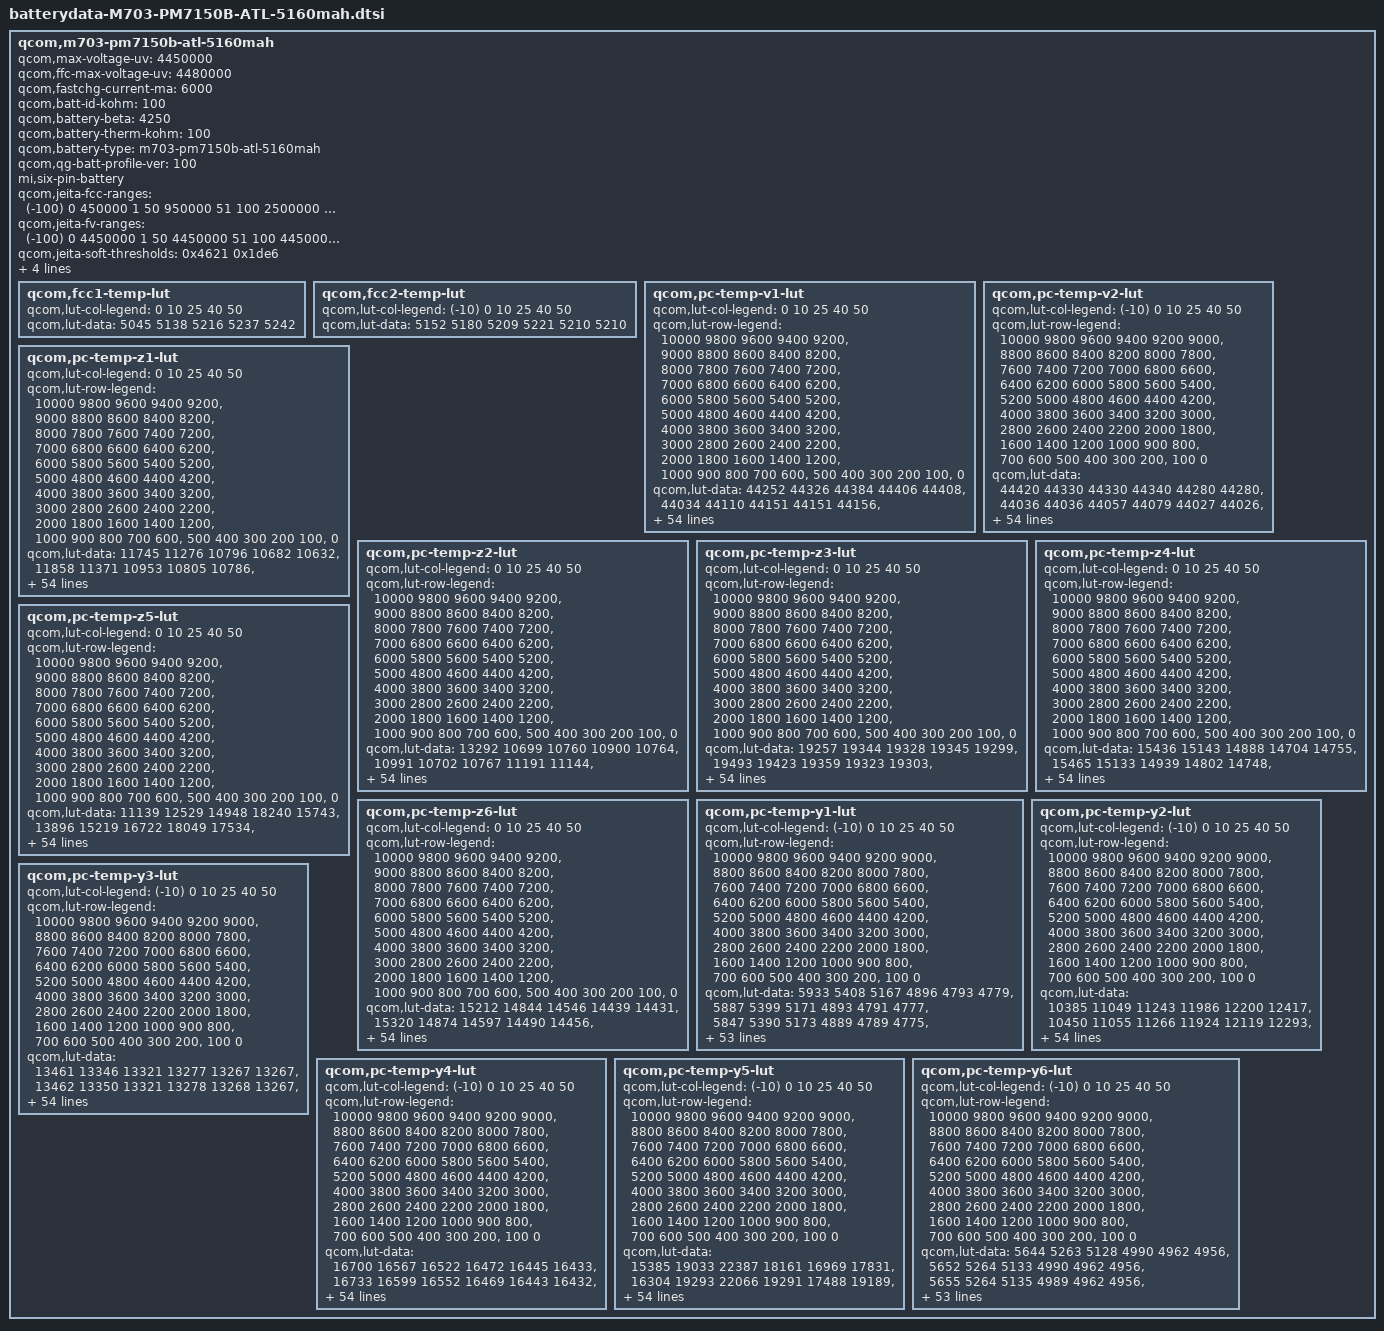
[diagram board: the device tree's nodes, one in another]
/*
 * Copyright (c) 2019, The Linux Foundation. All rights reserved.
 * Copyright (C) 2021 XiaoMi, Inc.
 *
 * This program is free software; you can redistribute it and/or modify
 * it under the terms of the GNU General Public License version 2 and
 * only version 2 as published by the Free Software Foundation.
 *
 * This program is distributed in the hope that it will be useful,
 * but WITHOUT ANY WARRANTY; without even the implied warranty of
 * MERCHANTABILITY or FITNESS FOR A PARTICULAR PURPOSE.  See the
 * GNU General Public License for more details.
 */
/* 4622819_LC_M700_ATL_5160mAH_PM7150B_averaged_Master_May26th2020 */

 qcom,m703-pm7150b-atl-5160mah {
	qcom,max-voltage-uv = <4450000>;
	qcom,ffc-max-voltage-uv = <4480000>;
	//qcom,fg-cc-cv-threshold-uv = <4440000>;
	qcom,fastchg-current-ma = <6000>;
	qcom,batt-id-kohm = <100>;
	qcom,battery-beta = <4250>;
	qcom,battery-therm-kohm = <100>;
	qcom,battery-type = "m703-pm7150b-atl-5160mah";
	qcom,qg-batt-profile-ver = <100>;
	mi,six-pin-battery;

	qcom,jeita-fcc-ranges = <(-100)  0   450000
                                1  50   950000
				51  100  2500000
				101 150  4000000
				151 480  6000000
				481 580  2500000>;

	qcom,jeita-fv-ranges = <(-100)   0   4450000
                                1   50   4450000
				51  100  4450000
				101 150  4450000
				151 480  4480000
				481 580  4100000>;

	/* COOL = 15 degc, WARM = 48 degC */
	qcom,jeita-soft-thresholds = <0x4621 0x1de6>;
	/* COLD = -10 degC, HOT = 58 degC*/
	qcom,jeita-hard-thresholds = <0x6226 0x15f7>;
	/* COOL hys = 18 degC, WARM hys = 45 degC */
	qcom,jeita-soft-hys-thresholds = <0x4206 0x20b8>;
	qcom,jeita-soft-fcc-ua = <4100000 2500000>;
	qcom,jeita-soft-fv-uv = <4450000 4100000>;

	qcom,fcc1-temp-lut {
		qcom,lut-col-legend = <0 10 25 40 50>;
		qcom,lut-data = <5045 5138 5216 5237 5242>;
	};

	qcom,fcc2-temp-lut {
		qcom,lut-col-legend = <(-10) 0 10 25 40 50>;
		qcom,lut-data = <5152 5180 5209 5221 5210 5210>;
	};

	qcom,pc-temp-v1-lut {
		qcom,lut-col-legend = <0 10 25 40 50>;
		qcom,lut-row-legend = <10000 9800 9600 9400 9200>,
			<9000 8800 8600 8400 8200>,
			<8000 7800 7600 7400 7200>,
			<7000 6800 6600 6400 6200>,
			<6000 5800 5600 5400 5200>,
			<5000 4800 4600 4400 4200>,
			<4000 3800 3600 3400 3200>,
			<3000 2800 2600 2400 2200>,
			<2000 1800 1600 1400 1200>,
			<1000 900 800 700 600>,
			<500 400 300 200 100>,
			<0>;
		qcom,lut-data = <44252 44326 44384 44406 44408>,
			<44034 44110 44151 44151 44156>,
			<43814 43893 43932 43929 43933>,
			<43596 43678 43715 43713 43716>,
			<43372 43463 43496 43496 43499>,
			<43136 43239 43276 43280 43282>,
			<42894 43001 43044 43054 43058>,
			<42654 42757 42801 42816 42824>,
			<42412 42515 42556 42574 42586>,
			<42174 42272 42311 42332 42346>,
			<41943 42033 42067 42089 42104>,
			<41717 41796 41827 41849 41865>,
			<41494 41564 41590 41611 41628>,
			<41274 41340 41357 41377 41395>,
			<41060 41124 41132 41150 41170>,
			<40858 40913 40914 40930 40950>,
			<40663 40705 40705 40719 40739>,
			<40470 40503 40503 40516 40533>,
			<40278 40320 40312 40323 40336>,
			<40090 40153 40138 40144 40153>,
			<39912 39968 39964 39969 39976>,
			<39745 39732 39752 39765 39775>,
			<39557 39486 39506 39530 39549>,
			<39288 39282 39290 39311 39335>,
			<39026 39101 39109 39118 39140>,
			<38894 38951 38952 38947 38963>,
			<38820 38835 38821 38810 38821>,
			<38753 38735 38710 38696 38703>,
			<38676 38637 38608 38592 38595>,
			<38599 38542 38510 38493 38492>,
			<38530 38460 38422 38402 38399>,
			<38464 38389 38345 38321 38312>,
			<38404 38328 38276 38247 38232>,
			<38346 38271 38215 38179 38160>,
			<38292 38221 38163 38120 38096>,
			<38250 38175 38115 38063 38034>,
			<38220 38137 38067 38004 37962>,
			<38186 38099 38020 37944 37883>,
			<38126 38040 37957 37872 37799>,
			<38033 37952 37873 37785 37715>,
			<37926 37847 37772 37684 37619>,
			<37801 37726 37655 37565 37500>,
			<37656 37583 37517 37427 37359>,
			<37478 37407 37350 37266 37195>,
			<37329 37241 37191 37121 37051>,
			<37214 37130 37087 37027 36962>,
			<37167 37101 37060 37004 36939>,
			<37136 37082 37044 36987 36923>,
			<37110 37052 37024 36970 36911>,
			<37073 37023 36985 36925 36866>,
			<36921 36817 36749 36653 36609>,
			<36484 36368 36304 36203 36178>,
			<35894 35765 35710 35614 35605>,
			<35074 34925 34895 34801 34835>,
			<33639 33502 33608 33529 33659>,
			<30000 30000 30000 30000 30000>;
	};

	qcom,pc-temp-v2-lut {
		qcom,lut-col-legend = <(-10) 0 10 25 40 50>;
		qcom,lut-row-legend = <10000 9800 9600 9400 9200 9000>,
			<8800 8600 8400 8200 8000 7800>,
			<7600 7400 7200 7000 6800 6600>,
			<6400 6200 6000 5800 5600 5400>,
			<5200 5000 4800 4600 4400 4200>,
			<4000 3800 3600 3400 3200 3000>,
			<2800 2600 2400 2200 2000 1800>,
			<1600 1400 1200 1000 900 800>,
			<700 600 500 400 300 200>,
			<100 0>;
		qcom,lut-data = <44420 44330 44330 44340 44280 44280>,
			<44036 44036 44057 44079 44027 44026>,
			<43696 43766 43800 43832 43785 43784>,
			<43412 43523 43565 43602 43557 43556>,
			<43174 43307 43351 43388 43344 43344>,
			<42943 43090 43132 43169 43126 43127>,
			<42699 42858 42897 42934 42893 42896>,
			<42456 42621 42656 42692 42654 42658>,
			<42218 42383 42416 42449 42414 42419>,
			<41985 42139 42173 42205 42170 42176>,
			<41753 41898 41933 41962 41930 41936>,
			<41509 41658 41696 41722 41692 41698>,
			<41271 41422 41463 41484 41458 41464>,
			<41079 41199 41233 41252 41229 41234>,
			<40934 40986 41006 41026 41006 41010>,
			<40759 40781 40787 40807 40790 40793>,
			<40461 40590 40577 40595 40580 40584>,
			<40099 40398 40374 40391 40377 40382>,
			<39823 40171 40182 40200 40186 40191>,
			<39604 39906 39999 40017 40005 40008>,
			<39397 39647 39791 39817 39809 39812>,
			<39183 39400 39523 39586 39582 39589>,
			<38975 39168 39253 39353 39351 39362>,
			<38778 38970 39040 39134 39139 39152>,
			<38582 38794 38856 38924 38937 38950>,
			<38425 38638 38698 38756 38772 38786>,
			<38321 38496 38561 38625 38644 38659>,
			<38238 38368 38441 38512 38533 38548>,
			<38165 38248 38331 38405 38430 38441>,
			<38100 38134 38231 38307 38334 38341>,
			<38040 38048 38138 38217 38246 38250>,
			<37983 37986 38048 38136 38164 38167>,
			<37928 37936 37968 38060 38088 38089>,
			<37871 37891 37903 37991 38019 38016>,
			<37815 37851 37847 37925 37954 37945>,
			<37755 37811 37796 37854 37872 37854>,
			<37689 37776 37756 37779 37763 37726>,
			<37619 37736 37711 37699 37650 37596>,
			<37543 37680 37645 37614 37553 37494>,
			<37461 37603 37560 37523 37462 37400>,
			<37369 37503 37457 37429 37364 37302>,
			<37260 37351 37325 37330 37261 37200>,
			<37139 37182 37182 37213 37141 37080>,
			<37006 37013 37028 37074 37001 36941>,
			<36880 36859 36884 36924 36876 36816>,
			<36767 36774 36814 36886 36849 36791>,
			<36719 36742 36769 36868 36835 36779>,
			<36663 36709 36731 36847 36820 36762>,
			<36612 36661 36673 36819 36793 36726>,
			<36550 36578 36535 36741 36679 36571>,
			<36438 36362 36169 36437 36298 36175>,
			<36180 35898 35592 35918 35774 35633>,
			<35673 35197 34836 35248 35070 34918>,
			<34885 34243 33745 34328 34082 33902>,
			<33994 32837 32031 32879 32605 32572>,
			<32884 29022 27352 27492 28129 28778>;
	};

	qcom,pc-temp-z1-lut {
		qcom,lut-col-legend = <0 10 25 40 50>;
		qcom,lut-row-legend = <10000 9800 9600 9400 9200>,
			<9000 8800 8600 8400 8200>,
			<8000 7800 7600 7400 7200>,
			<7000 6800 6600 6400 6200>,
			<6000 5800 5600 5400 5200>,
			<5000 4800 4600 4400 4200>,
			<4000 3800 3600 3400 3200>,
			<3000 2800 2600 2400 2200>,
			<2000 1800 1600 1400 1200>,
			<1000 900 800 700 600>,
			<500 400 300 200 100>,
			<0>;
		qcom,lut-data = <11745 11276 10796 10682 10632>,
			<11858 11371 10953 10805 10786>,
			<11881 11429 10981 10823 10802>,
			<11884 11433 10990 10831 10810>,
			<11885 11429 10986 10833 10812>,
			<11871 11424 10979 10834 10813>,
			<11847 11416 10975 10835 10814>,
			<11841 11404 10972 10834 10816>,
			<11840 11391 10970 10834 10818>,
			<11839 11374 10967 10834 10820>,
			<11830 11364 10964 10833 10821>,
			<11810 11362 10962 10832 10821>,
			<11799 11360 10961 10830 10820>,
			<11794 11354 10960 10829 10820>,
			<11790 11343 10960 10829 10821>,
			<11784 11337 10959 10831 10822>,
			<11778 11338 10959 10831 10823>,
			<11776 11340 10960 10832 10824>,
			<11776 11341 10961 10832 10825>,
			<11778 11344 10962 10833 10826>,
			<11783 11346 10963 10834 10826>,
			<11792 11348 10965 10835 10828>,
			<11796 11350 10967 10837 10829>,
			<11784 11353 10969 10839 10832>,
			<11768 11357 10972 10841 10834>,
			<11771 11361 10976 10844 10837>,
			<11795 11369 10980 10847 10838>,
			<11810 11377 10984 10850 10839>,
			<11809 11377 10988 10852 10840>,
			<11806 11369 10991 10853 10843>,
			<11807 11364 10995 10854 10847>,
			<11813 11369 10998 10856 10848>,
			<11820 11378 11002 10858 10849>,
			<11824 11384 11006 10861 10849>,
			<11828 11390 11008 10863 10851>,
			<11831 11395 11011 10865 10853>,
			<11834 11400 11015 10867 10855>,
			<11836 11403 11018 10870 10858>,
			<11841 11406 11022 10872 10860>,
			<11847 11407 11027 10874 10862>,
			<11850 11410 11031 10875 10863>,
			<11851 11423 11034 10877 10864>,
			<11855 11440 11036 10880 10865>,
			<11906 11452 11043 10884 10866>,
			<11889 11453 11048 10884 10867>,
			<11905 11451 11049 10883 10870>,
			<11903 11436 11051 10885 10869>,
			<11903 11435 11055 10886 10871>,
			<11914 11455 11056 10888 10870>,
			<11909 11443 11060 10890 10873>,
			<11935 11472 11069 10892 10875>,
			<11934 11480 11066 10897 10879>,
			<11959 11494 11079 10902 10884>,
			<11967 11497 11092 10910 10890>,
			<11967 11497 11092 10910 10890>,
			<11967 11497 11092 10910 10890>;
	};

	qcom,pc-temp-z2-lut {
		qcom,lut-col-legend = <0 10 25 40 50>;
		qcom,lut-row-legend = <10000 9800 9600 9400 9200>,
			<9000 8800 8600 8400 8200>,
			<8000 7800 7600 7400 7200>,
			<7000 6800 6600 6400 6200>,
			<6000 5800 5600 5400 5200>,
			<5000 4800 4600 4400 4200>,
			<4000 3800 3600 3400 3200>,
			<3000 2800 2600 2400 2200>,
			<2000 1800 1600 1400 1200>,
			<1000 900 800 700 600>,
			<500 400 300 200 100>,
			<0>;
		qcom,lut-data = <13292 10699 10760 10900 10764>,
			<10991 10702 10767 11191 11144>,
			<10544 10702 10937 11236 11171>,
			<10508 10698 11060 11252 11216>,
			<10480 10680 11030 11244 11268>,
			<10441 10658 10969 11219 11330>,
			<10406 10623 10931 11203 11344>,
			<10387 10588 10903 11197 11239>,
			<10374 10573 10891 11189 11139>,
			<10368 10563 10910 11151 11136>,
			<10369 10561 10945 11090 11143>,
			<10374 10583 10974 11077 11157>,
			<10381 10617 11001 11107 11211>,
			<10399 10639 11018 11131 11253>,
			<10424 10655 11025 11116 11246>,
			<10455 10672 11030 11089 11229>,
			<10492 10691 11043 11086 11234>,
			<10520 10708 11068 11109 11294>,
			<10540 10717 11079 11143 11349>,
			<10555 10722 11076 11193 11365>,
			<10564 10729 11071 11255 11377>,
			<10571 10743 11080 11302 11391>,
			<10575 10755 11114 11344 11408>,
			<10576 10751 11140 11362 11416>,
			<10577 10726 11156 11346 11323>,
			<10578 10712 11166 11309 11173>,
			<10581 10719 11125 11241 11100>,
			<10584 10727 11007 11112 11051>,
			<10590 10724 10960 11042 11034>,
			<10596 10708 10967 11028 11035>,
			<10600 10699 10980 11020 11039>,
			<10601 10707 11002 11033 11062>,
			<10604 10724 11038 11083 11134>,
			<10613 10742 11075 11138 11209>,
			<10629 10767 11114 11195 11284>,
			<10635 10785 11153 11258 11355>,
			<10637 10790 11188 11325 11408>,
			<10638 10795 11220 11396 11452>,
			<10647 10801 11250 11460 11480>,
			<10664 10811 11282 11529 11493>,
			<10670 10816 11300 11570 11508>,
			<10652 10810 11298 11555 11552>,
			<10643 10805 11291 11519 11600>,
			<10679 10810 11269 11481 11544>,
			<10443 10917 11265 11450 11442>,
			<10460 11033 11302 11490 11547>,
			<11036 11017 11273 11473 11515>,
			<10801 11223 11222 11408 11499>,
			<10323 11051 11280 11451 11673>,
			<10381 11775 11254 11653 11690>,
			<10512 11294 11307 11221 11264>,
			<10271 11384 11208 11152 11183>,
			<9929 11200 11173 11105 11185>,
			<9838 10959 11119 11027 11037>,
			<9838 10959 11119 11027 11037>,
			<9838 10959 11119 11027 11037>;
	};

	qcom,pc-temp-z3-lut {
		qcom,lut-col-legend = <0 10 25 40 50>;
		qcom,lut-row-legend = <10000 9800 9600 9400 9200>,
			<9000 8800 8600 8400 8200>,
			<8000 7800 7600 7400 7200>,
			<7000 6800 6600 6400 6200>,
			<6000 5800 5600 5400 5200>,
			<5000 4800 4600 4400 4200>,
			<4000 3800 3600 3400 3200>,
			<3000 2800 2600 2400 2200>,
			<2000 1800 1600 1400 1200>,
			<1000 900 800 700 600>,
			<500 400 300 200 100>,
			<0>;
		qcom,lut-data = <19257 19344 19328 19345 19299>,
			<19493 19423 19359 19323 19303>,
			<19581 19476 19376 19336 19310>,
			<19620 19494 19386 19345 19318>,
			<19641 19503 19391 19348 19325>,
			<19657 19508 19394 19349 19332>,
			<19667 19513 19396 19349 19334>,
			<19669 19515 19397 19347 19331>,
			<19668 19515 19398 19345 19327>,
			<19665 19510 19391 19340 19324>,
			<19660 19505 19380 19333 19321>,
			<19652 19500 19377 19330 19320>,
			<19645 19495 19376 19329 19319>,
			<19641 19488 19376 19329 19318>,
			<19637 19480 19374 19328 19316>,
			<19630 19476 19372 19326 19311>,
			<19622 19477 19370 19324 19308>,
			<19614 19479 19367 19320 19306>,
			<19604 19477 19364 19317 19304>,
			<19597 19469 19362 19315 19303>,
			<19598 19465 19360 19313 19303>,
			<19604 19474 19361 19314 19304>,
			<19609 19486 19368 19319 19310>,
			<19613 19485 19371 19326 19318>,
			<19615 19471 19372 19340 19326>,
			<19613 19464 19373 19354 19332>,
			<19602 19474 19378 19355 19333>,
			<19594 19489 19388 19352 19331>,
			<19597 19493 19392 19348 19329>,
			<19601 19494 19391 19344 19326>,
			<19602 19495 19390 19340 19323>,
			<19602 19491 19386 19336 19320>,
			<19601 19484 19381 19330 19316>,
			<19600 19479 19376 19326 19313>,
			<19599 19475 19372 19324 19308>,
			<19597 19473 19369 19322 19305>,
			<19592 19471 19367 19321 19306>,
			<19587 19470 19367 19321 19309>,
			<19583 19468 19366 19321 19310>,
			<19579 19463 19363 19322 19310>,
			<19574 19459 19361 19323 19309>,
			<19568 19454 19360 19325 19310>,
			<19559 19449 19358 19325 19313>,
			<19544 19445 19356 19324 19315>,
			<19346 19426 19350 19318 19314>,
			<19269 19408 19339 19310 19306>,
			<19315 19396 19339 19309 19303>,
			<19302 19329 19331 19308 19303>,
			<19263 19397 19333 19304 19290>,
			<19263 19293 19330 19298 19295>,
			<19262 19334 19332 19323 19310>,
			<19263 19314 19339 19321 19311>,
			<19273 19318 19339 19322 19314>,
			<19277 19335 19343 19323 19313>,
			<19277 19335 19343 19323 19313>,
			<19277 19335 19343 19323 19313>;
	};

	qcom,pc-temp-z4-lut {
		qcom,lut-col-legend = <0 10 25 40 50>;
		qcom,lut-row-legend = <10000 9800 9600 9400 9200>,
			<9000 8800 8600 8400 8200>,
			<8000 7800 7600 7400 7200>,
			<7000 6800 6600 6400 6200>,
			<6000 5800 5600 5400 5200>,
			<5000 4800 4600 4400 4200>,
			<4000 3800 3600 3400 3200>,
			<3000 2800 2600 2400 2200>,
			<2000 1800 1600 1400 1200>,
			<1000 900 800 700 600>,
			<500 400 300 200 100>,
			<0>;
		qcom,lut-data = <15436 15143 14888 14704 14755>,
			<15465 15133 14939 14802 14748>,
			<15443 15108 14898 14783 14740>,
			<15323 15064 14852 14757 14728>,
			<15197 14983 14818 14739 14715>,
			<15110 14915 14788 14724 14699>,
			<15032 14868 14762 14709 14687>,
			<14972 14830 14738 14695 14679>,
			<14924 14801 14721 14685 14672>,
			<14884 14777 14714 14682 14668>,
			<14853 14759 14708 14680 14665>,
			<14827 14741 14701 14678 14661>,
			<14804 14728 14693 14671 14656>,
			<14782 14724 14686 14665 14651>,
			<14765 14723 14680 14659 14648>,
			<14755 14720 14675 14655 14646>,
			<14749 14717 14672 14651 14643>,
			<14747 14712 14668 14648 14640>,
			<14756 14709 14667 14646 14636>,
			<14766 14706 14666 14643 14632>,
			<14763 14705 14666 14642 14630>,
			<14750 14724 14678 14649 14634>,
			<14743 14757 14719 14683 14659>,
			<14799 14785 14744 14703 14674>,
			<14872 14815 14752 14698 14674>,
			<14882 14827 14757 14689 14674>,
			<14866 14803 14748 14682 14671>,
			<14848 14767 14720 14674 14663>,
			<14830 14752 14702 14668 14656>,
			<14812 14743 14693 14663 14651>,
			<14799 14739 14688 14659 14647>,
			<14787 14738 14686 14656 14643>,
			<14780 14737 14686 14653 14640>,
			<14778 14737 14685 14652 14639>,
			<14777 14737 14685 14652 14638>,
			<14775 14736 14685 14652 14638>,
			<14768 14735 14686 14655 14641>,
			<14760 14732 14690 14662 14651>,
			<14754 14728 14692 14664 14654>,
			<14747 14725 14692 14664 14652>,
			<14738 14719 14693 14663 14649>,
			<14723 14707 14686 14659 14644>,
			<14708 14691 14673 14653 14639>,
			<14696 14680 14666 14650 14639>,
			<14840 14664 14657 14648 14635>,
			<14893 14652 14649 14642 14628>,
			<14842 14657 14639 14634 14625>,
			<14853 14724 14636 14625 14614>,
			<14887 14644 14624 14618 14616>,
			<14884 14758 14627 14623 14609>,
			<14884 14719 14640 14614 14613>,
			<14890 14744 14633 14619 14615>,
			<14889 14746 14635 14618 14613>,
			<14902 14735 14632 14619 14615>,
			<14902 14735 14632 14619 14615>,
			<14902 14735 14632 14619 14615>;
	};

	qcom,pc-temp-z5-lut {
		qcom,lut-col-legend = <0 10 25 40 50>;
		qcom,lut-row-legend = <10000 9800 9600 9400 9200>,
			<9000 8800 8600 8400 8200>,
			<8000 7800 7600 7400 7200>,
			<7000 6800 6600 6400 6200>,
			<6000 5800 5600 5400 5200>,
			<5000 4800 4600 4400 4200>,
			<4000 3800 3600 3400 3200>,
			<3000 2800 2600 2400 2200>,
			<2000 1800 1600 1400 1200>,
			<1000 900 800 700 600>,
			<500 400 300 200 100>,
			<0>;
		qcom,lut-data = <11139 12529 14948 18240 15743>,
			<13896 15219 16722 18049 17534>,
			<15543 17240 18249 20262 18782>,
			<16587 18359 19231 21770 20753>,
			<17538 19071 19724 22064 22669>,
			<18572 19865 20080 22183 24724>,
			<19588 20945 20708 22433 25377>,
			<20613 22038 21784 23165 25351>,
			<21670 22857 22372 23729 25300>,
			<22651 23503 22118 23148 25072>,
			<23403 24362 21738 21886 24647>,
			<24082 26203 21875 21618 24646>,
			<25167 27888 22933 22393 25861>,
			<27355 27918 24068 23355 26862>,
			<29673 27350 24976 24234 26259>,
			<31394 27108 25839 25025 25069>,
			<32894 29869 26603 25104 24822>,
			<33317 33339 27293 24651 25257>,
			<31928 33247 27927 24347 25979>,
			<30379 31235 28542 24957 27952>,
			<31717 30258 29081 25896 30429>,
			<37196 37257 29496 25849 30632>,
			<41470 46330 29853 24841 29143>,
			<43714 44466 29825 24139 27340>,
			<45187 32059 25486 23959 25146>,
			<43837 25250 20679 23860 23217>,
			<36584 26555 21122 24126 23289>,
			<31892 29169 24073 25365 24776>,
			<32577 32505 27321 26780 26433>,
			<34163 37443 31129 28379 28024>,
			<35964 40786 34618 29887 29631>,
			<38384 42055 36673 30684 31076>,
			<40867 42917 38185 31183 32433>,
			<43312 43735 39388 32019 33373>,
			<45566 44543 40547 34393 34073>,
			<46026 44891 41215 36417 34482>,
			<44561 44774 41188 35796 34353>,
			<43188 44476 41012 33773 33871>,
			<43286 43655 40312 32521 33385>,
			<43730 41216 36128 31839 32815>,
			<43838 39046 32772 31488 32442>,
			<42060 37911 33231 32772 34449>,
			<39443 37040 33956 34753 37647>,
			<36594 36377 32555 32708 37527>,
			<18602 35669 30300 26975 35307>,
			<11947 32409 27698 24064 28035>,
			<12784 26266 30522 25866 27587>,
			<12423 14759 27356 29400 36957>,
			<11743 28035 32088 32863 27511>,
			<11710 12778 28779 24204 33794>,
			<11747 14926 23010 44383 43324>,
			<11714 13601 25113 35484 41387>,
			<11713 13591 24041 34798 44676>,
			<12068 14472 25077 32664 37024>,
			<12068 14472 25077 32664 37024>,
			<12068 14472 25077 32664 37024>;
	};

	qcom,pc-temp-z6-lut {
		qcom,lut-col-legend = <0 10 25 40 50>;
		qcom,lut-row-legend = <10000 9800 9600 9400 9200>,
			<9000 8800 8600 8400 8200>,
			<8000 7800 7600 7400 7200>,
			<7000 6800 6600 6400 6200>,
			<6000 5800 5600 5400 5200>,
			<5000 4800 4600 4400 4200>,
			<4000 3800 3600 3400 3200>,
			<3000 2800 2600 2400 2200>,
			<2000 1800 1600 1400 1200>,
			<1000 900 800 700 600>,
			<500 400 300 200 100>,
			<0>;
		qcom,lut-data = <15212 14844 14546 14439 14431>,
			<15320 14874 14597 14490 14456>,
			<15325 14885 14591 14489 14457>,
			<15268 14875 14582 14487 14458>,
			<15205 14834 14571 14484 14457>,
			<15156 14797 14557 14478 14454>,
			<15110 14771 14546 14471 14451>,
			<15070 14749 14536 14465 14446>,
			<15036 14729 14528 14459 14441>,
			<15005 14711 14519 14454 14438>,
			<14978 14696 14512 14451 14435>,
			<14954 14684 14506 14447 14432>,
			<14934 14673 14502 14443 14430>,
			<14917 14666 14498 14440 14427>,
			<14903 14660 14494 14437 14424>,
			<14892 14656 14491 14434 14421>,
			<14883 14654 14488 14431 14418>,
			<14878 14653 14485 14428 14415>,
			<14877 14650 14483 14425 14413>,
			<14876 14644 14481 14423 14411>,
			<14875 14642 14481 14422 14410>,
			<14874 14656 14486 14425 14412>,
			<14874 14677 14508 14442 14426>,
			<14900 14688 14522 14456 14438>,
			<14936 14696 14528 14463 14444>,
			<14939 14699 14531 14467 14448>,
			<14928 14695 14529 14466 14447>,
			<14918 14689 14524 14461 14443>,
			<14914 14686 14519 14456 14439>,
			<14910 14685 14516 14452 14436>,
			<14907 14684 14513 14448 14432>,
			<14903 14681 14510 14444 14429>,
			<14901 14678 14508 14441 14426>,
			<14902 14678 14506 14438 14423>,
			<14902 14677 14504 14437 14420>,
			<14903 14677 14503 14436 14419>,
			<14901 14677 14504 14437 14421>,
			<14899 14678 14506 14439 14427>,
			<14900 14678 14507 14441 14429>,
			<14902 14677 14507 14442 14428>,
			<14903 14676 14506 14443 14427>,
			<14901 14672 14503 14442 14426>,
			<14898 14667 14498 14439 14425>,
			<14895 14665 14496 14438 14426>,
			<14870 14655 14489 14435 14424>,
			<14858 14644 14482 14428 14417>,
			<14857 14642 14478 14424 14414>,
			<14856 14637 14473 14419 14410>,
			<14855 14639 14469 14414 14403>,
			<14857 14639 14470 14414 14403>,
			<14865 14647 14478 14424 14413>,
			<14874 14653 14480 14426 14416>,
			<14884 14663 14483 14427 14418>,
			<14904 14676 14486 14430 14419>,
			<14904 14676 14486 14430 14419>,
			<14904 14676 14486 14430 14419>;
	};

	qcom,pc-temp-y1-lut {
		qcom,lut-col-legend = <(-10) 0 10 25 40 50>;
		qcom,lut-row-legend = <10000 9800 9600 9400 9200 9000>,
			<8800 8600 8400 8200 8000 7800>,
			<7600 7400 7200 7000 6800 6600>,
			<6400 6200 6000 5800 5600 5400>,
			<5200 5000 4800 4600 4400 4200>,
			<4000 3800 3600 3400 3200 3000>,
			<2800 2600 2400 2200 2000 1800>,
			<1600 1400 1200 1000 900 800>,
			<700 600 500 400 300 200>,
			<100 0>;
		qcom,lut-data = <5933 5408 5167 4896 4793 4779>,
			<5887 5399 5171 4893 4791 4777>,
			<5847 5390 5173 4889 4789 4775>,
			<5815 5381 5173 4886 4788 4774>,
			<5794 5374 5172 4882 4786 4772>,
			<5786 5369 5169 4879 4785 4771>,
			<5796 5366 5163 4876 4784 4770>,
			<5812 5364 5154 4873 4783 4769>,
			<5811 5360 5151 4870 4781 4768>,
			<5792 5355 5149 4867 4778 4768>,
			<5779 5352 5147 4865 4777 4768>,
			<5791 5354 5143 4863 4777 4768>,
			<5810 5356 5138 4862 4777 4769>,
			<5816 5355 5134 4860 4777 4769>,
			<5818 5350 5131 4858 4777 4769>,
			<5819 5347 5130 4857 4777 4769>,
			<5820 5350 5131 4857 4777 4768>,
			<5822 5356 5133 4856 4777 4767>,
			<5825 5362 5133 4856 4777 4767>,
			<5832 5368 5130 4856 4777 4768>,
			<5837 5371 5127 4856 4777 4768>,
			<5840 5365 5122 4858 4778 4768>,
			<5842 5358 5117 4861 4779 4769>,
			<5844 5359 5118 4861 4780 4770>,
			<5846 5369 5123 4861 4780 4771>,
			<5847 5377 5129 4861 4781 4772>,
			<5840 5380 5135 4863 4781 4773>,
			<5828 5382 5138 4866 4782 4773>,
			<5827 5381 5138 4869 4783 4773>,
			<5836 5377 5136 4872 4784 4773>,
			<5842 5375 5134 4874 4785 4773>,
			<5842 5377 5132 4876 4788 4774>,
			<5842 5380 5130 4878 4791 4775>,
			<5842 5378 5136 4880 4792 4777>,
			<5842 5371 5149 4883 4792 4779>,
			<5842 5367 5153 4885 4793 4780>,
			<5839 5378 5150 4887 4794 4780>,
			<5831 5392 5146 4889 4794 4780>,
			<5821 5390 5144 4891 4796 4780>,
			<5801 5378 5143 4894 4798 4782>,
			<5789 5373 5144 4895 4798 4782>,
			<5794 5380 5156 4895 4798 4783>,
			<5804 5386 5169 4897 4798 4784>,
			<5824 5388 5178 4902 4799 4786>,
			<5831 5410 5175 4903 4801 4784>,
			<5836 5396 5187 4904 4799 4788>,
			<5866 5402 5184 4906 4803 4786>,
			<5873 5413 5185 4908 4802 4787>,
			<5884 5408 5185 4912 4804 4787>,
			<5900 5404 5188 4913 4803 4788>,
			<5944 5444 5199 4915 4805 4788>,
			<6017 5512 5192 4919 4807 4790>,
			<6152 5637 5230 4926 4810 4794>,
			<6388 5885 5359 4940 4813 4798>,
			<6388 5885 5359 4940 4813 4798>,
			<6388 5885 5359 4940 4813 4798>;
	};

	qcom,pc-temp-y2-lut {
		qcom,lut-col-legend = <(-10) 0 10 25 40 50>;
		qcom,lut-row-legend = <10000 9800 9600 9400 9200 9000>,
			<8800 8600 8400 8200 8000 7800>,
			<7600 7400 7200 7000 6800 6600>,
			<6400 6200 6000 5800 5600 5400>,
			<5200 5000 4800 4600 4400 4200>,
			<4000 3800 3600 3400 3200 3000>,
			<2800 2600 2400 2200 2000 1800>,
			<1600 1400 1200 1000 900 800>,
			<700 600 500 400 300 200>,
			<100 0>;
		qcom,lut-data = <10385 11049 11243 11986 12200 12417>,
			<10450 11055 11266 11924 12119 12293>,
			<10528 11055 11273 11807 12041 12157>,
			<10606 11050 11269 11674 11968 12027>,
			<10671 11041 11256 11567 11905 11919>,
			<10710 11029 11238 11526 11855 11849>,
			<10729 11009 11208 11531 11819 11810>,
			<10741 10988 11172 11537 11787 11783>,
			<10741 10983 11150 11528 11750 11758>,
			<10731 10982 11134 11485 11707 11736>,
			<10725 10982 11121 11463 11670 11712>,
			<10786 10986 11108 11490 11639 11669>,
			<10884 10998 11098 11522 11612 11632>,
			<10893 11021 11101 11514 11590 11634>,
			<10837 11073 11119 11473 11570 11655>,
			<10798 11126 11147 11456 11561 11665>,
			<10851 11176 11209 11474 11560 11646>,
			<10937 11217 11291 11511 11559 11625>,
			<10960 11229 11373 11586 11582 11655>,
			<10965 11234 11462 11717 11667 11768>,
			<10966 11236 11493 11786 11754 11862>,
			<10956 11231 11454 11805 11831 11911>,
			<10926 11224 11413 11819 11909 11962>,
			<10786 11228 11419 11834 11995 12068>,
			<10195 11251 11448 11848 12083 12224>,
			<9774 11272 11469 11864 12106 12304>,
			<9737 11283 11479 11884 12024 12333>,
			<9716 11295 11488 11908 11943 12348>,
			<9707 11331 11503 11946 12013 12327>,
			<9702 11406 11520 11990 12208 12274>,
			<9698 11440 11524 11996 12308 12255>,
			<9693 11392 11501 11943 12336 12260>,
			<9688 11312 11476 11901 12359 12268>,
			<9685 11252 11469 11943 12405 12297>,
			<9682 11198 11466 12025 12458 12351>,
			<9680 11142 11458 12040 12467 12379>,
			<9677 11086 11435 12005 12410 12389>,
			<9674 11025 11402 11968 12327 12399>,
			<9672 10956 11357 11952 12222 12416>,
			<9671 10875 11294 11938 12107 12435>,
			<9670 10727 11213 11899 12081 12411>,
			<9669 10136 11098 11811 12092 12224>,
			<9667 9763 10984 11800 12119 12189>,
			<9666 9722 10872 11822 12165 12284>,
			<9665 9697 10741 11797 12139 12151>,
			<9663 9685 10663 11726 11939 11977>,
			<9662 9679 10235 11742 11908 11913>,
			<9660 9674 10123 11702 11896 11774>,
			<9659 9669 10018 11665 11856 11658>,
			<9657 9664 9867 11615 11838 11882>,
			<9652 9659 9746 11625 11806 11808>,
			<9651 9653 9679 11522 11682 11661>,
			<9650 9650 9660 11442 11547 11620>,
			<9650 9650 9659 11286 11399 11347>,
			<9650 9650 9659 11286 11399 11347>,
			<9650 9650 9659 11286 11399 11347>;
	};

	qcom,pc-temp-y3-lut {
		qcom,lut-col-legend = <(-10) 0 10 25 40 50>;
		qcom,lut-row-legend = <10000 9800 9600 9400 9200 9000>,
			<8800 8600 8400 8200 8000 7800>,
			<7600 7400 7200 7000 6800 6600>,
			<6400 6200 6000 5800 5600 5400>,
			<5200 5000 4800 4600 4400 4200>,
			<4000 3800 3600 3400 3200 3000>,
			<2800 2600 2400 2200 2000 1800>,
			<1600 1400 1200 1000 900 800>,
			<700 600 500 400 300 200>,
			<100 0>;
		qcom,lut-data = <13461 13346 13321 13277 13267 13267>,
			<13462 13350 13321 13278 13268 13267>,
			<13462 13353 13322 13280 13269 13268>,
			<13463 13357 13322 13282 13270 13268>,
			<13463 13359 13323 13283 13271 13269>,
			<13464 13362 13324 13283 13272 13269>,
			<13465 13363 13324 13283 13272 13269>,
			<13465 13364 13325 13283 13272 13269>,
			<13465 13365 13326 13283 13273 13270>,
			<13462 13366 13327 13286 13274 13271>,
			<13458 13367 13328 13287 13274 13271>,
			<13448 13364 13329 13286 13274 13272>,
			<13436 13361 13329 13284 13274 13272>,
			<13430 13359 13329 13284 13275 13272>,
			<13427 13357 13329 13284 13277 13272>,
			<13423 13356 13328 13284 13278 13273>,
			<13419 13355 13325 13285 13278 13274>,
			<13415 13354 13322 13287 13279 13275>,
			<13410 13353 13322 13288 13279 13275>,
			<13404 13349 13323 13290 13279 13274>,
			<13398 13344 13323 13291 13279 13274>,
			<13393 13340 13318 13289 13278 13273>,
			<13387 13337 13312 13287 13277 13272>,
			<13379 13334 13309 13284 13275 13271>,
			<13366 13331 13307 13281 13272 13268>,
			<13359 13329 13305 13280 13270 13267>,
			<13359 13326 13304 13279 13270 13268>,
			<13360 13323 13303 13279 13269 13269>,
			<13363 13316 13303 13278 13270 13269>,
			<13374 13305 13302 13278 13271 13269>,
			<13389 13300 13302 13278 13272 13268>,
			<13405 13305 13301 13279 13271 13268>,
			<13425 13311 13300 13279 13271 13268>,
			<13448 13315 13300 13280 13271 13268>,
			<13473 13318 13299 13280 13272 13269>,
			<13501 13321 13299 13280 13272 13269>,
			<13533 13327 13301 13279 13271 13268>,
			<13569 13334 13303 13278 13270 13268>,
			<13611 13339 13305 13277 13269 13268>,
			<13660 13343 13306 13277 13269 13267>,
			<13715 13348 13308 13277 13269 13267>,
			<13776 13354 13308 13278 13270 13269>,
			<13844 13364 13311 13279 13270 13270>,
			<13919 13386 13317 13280 13270 13270>,
			<14025 13416 13323 13279 13271 13268>,
			<14123 13448 13325 13280 13271 13269>,
			<14226 13483 13325 13279 13272 13272>,
			<14358 13538 13335 13281 13276 13273>,
			<14569 13621 13353 13287 13278 13273>,
			<14938 13768 13380 13291 13278 13272>,
			<16289 14154 13419 13288 13274 13271>,
			<20047 15973 13558 13288 13277 13272>,
			<31317 23677 14162 13292 13277 13274>,
			<64098 65535 18003 13299 13280 13276>,
			<64098 65535 18003 13299 13280 13276>,
			<64098 65535 18003 13299 13280 13276>;
	};

	qcom,pc-temp-y4-lut {
		qcom,lut-col-legend = <(-10) 0 10 25 40 50>;
		qcom,lut-row-legend = <10000 9800 9600 9400 9200 9000>,
			<8800 8600 8400 8200 8000 7800>,
			<7600 7400 7200 7000 6800 6600>,
			<6400 6200 6000 5800 5600 5400>,
			<5200 5000 4800 4600 4400 4200>,
			<4000 3800 3600 3400 3200 3000>,
			<2800 2600 2400 2200 2000 1800>,
			<1600 1400 1200 1000 900 800>,
			<700 600 500 400 300 200>,
			<100 0>;
		qcom,lut-data = <16700 16567 16522 16472 16445 16433>,
			<16733 16599 16552 16469 16443 16432>,
			<16799 16637 16577 16465 16441 16432>,
			<16876 16673 16595 16462 16439 16431>,
			<16939 16700 16607 16460 16437 16431>,
			<16966 16711 16611 16459 16436 16430>,
			<16964 16707 16605 16460 16436 16430>,
			<16961 16698 16595 16461 16437 16431>,
			<16962 16689 16587 16461 16437 16431>,
			<16971 16676 16580 16461 16438 16430>,
			<16984 16670 16578 16460 16439 16430>,
			<16998 16675 16578 16465 16442 16432>,
			<17018 16687 16579 16474 16445 16434>,
			<17053 16705 16582 16480 16447 16437>,
			<17125 16734 16592 16486 16448 16439>,
			<17168 16767 16606 16493 16450 16441>,
			<17068 16805 16636 16501 16455 16444>,
			<16896 16838 16671 16510 16463 16446>,
			<16825 16830 16691 16527 16474 16454>,
			<16800 16772 16708 16552 16490 16467>,
			<16775 16712 16711 16560 16496 16472>,
			<16727 16661 16656 16551 16493 16471>,
			<16678 16615 16583 16535 16487 16468>,
			<16664 16586 16545 16507 16474 16459>,
			<16659 16565 16519 16468 16448 16441>,
			<16657 16549 16506 16455 16439 16433>,
			<16666 16536 16500 16455 16440 16432>,
			<16680 16528 16497 16455 16441 16432>,
			<16683 16527 16497 16457 16443 16433>,
			<16683 16529 16496 16461 16445 16437>,
			<16683 16530 16495 16466 16448 16441>,
			<16684 16525 16489 16472 16454 16447>,
			<16687 16520 16485 16477 16461 16452>,
			<16691 16523 16484 16481 16468 16457>,
			<16699 16536 16485 16484 16475 16461>,
			<16708 16551 16487 16484 16475 16461>,
			<16718 16569 16499 16475 16458 16447>,
			<16730 16587 16512 16465 16443 16435>,
			<16737 16600 16517 16455 16440 16434>,
			<16742 16610 16521 16446 16438 16434>,
			<16744 16616 16526 16446 16437 16434>,
			<16738 16618 16533 16450 16437 16433>,
			<16729 16618 16543 16454 16437 16434>,
			<16726 16616 16555 16458 16439 16437>,
			<16728 16613 16553 16447 16425 16421>,
			<16718 16606 16548 16451 16434 16427>,
			<16725 16617 16573 16460 16437 16429>,
			<16754 16629 16600 16468 16443 16443>,
			<16783 16655 16638 16479 16469 16482>,
			<16824 16688 16685 16499 16494 16479>,
			<17051 16707 16707 16485 16441 16436>,
			<17993 16835 16759 16482 16446 16439>,
			<23248 18601 16891 16509 16456 16453>,
			<65535 33412 18541 16569 16501 16502>,
			<65535 33412 18541 16569 16501 16502>,
			<65535 33412 18541 16569 16501 16502>;
	};

	qcom,pc-temp-y5-lut {
		qcom,lut-col-legend = <(-10) 0 10 25 40 50>;
		qcom,lut-row-legend = <10000 9800 9600 9400 9200 9000>,
			<8800 8600 8400 8200 8000 7800>,
			<7600 7400 7200 7000 6800 6600>,
			<6400 6200 6000 5800 5600 5400>,
			<5200 5000 4800 4600 4400 4200>,
			<4000 3800 3600 3400 3200 3000>,
			<2800 2600 2400 2200 2000 1800>,
			<1600 1400 1200 1000 900 800>,
			<700 600 500 400 300 200>,
			<100 0>;
		qcom,lut-data = <15385 19033 22387 18161 16969 17831>,
			<16304 19293 22066 19291 17488 19189>,
			<17275 19564 21621 19972 18133 20322>,
			<18201 19821 21156 20318 18763 21181>,
			<18981 20037 20773 20442 19237 21722>,
			<19518 20187 20576 20451 19413 21900>,
			<19884 20293 20525 19447 19351 21554>,
			<20133 20365 20489 18081 19221 21073>,
			<20133 20329 20397 18074 19067 21124>,
			<19868 20046 20200 18809 18853 21632>,
			<19464 19608 19933 19167 18562 21895>,
			<18549 18565 19545 17936 17953 21137>,
			<17470 17262 19014 16209 17370 19936>,
			<17721 16612 18259 15458 17617 19145>,
			<20277 16189 17180 14976 18749 18478>,
			<22104 16039 16522 14825 19279 18252>,
			<22243 17697 16245 14847 18491 18908>,
			<22320 20341 16091 14899 17392 19674>,
			<22604 21691 16839 15066 16835 19176>,
			<23422 22533 19500 15561 16435 17371>,
			<23940 23146 21536 16439 16392 16650>,
			<23887 23682 22729 19478 18458 18275>,
			<23722 24045 23528 22175 20677 20026>,
			<22580 24059 23842 22240 20758 20171>,
			<17175 23910 24035 21996 20448 20177>,
			<13164 23658 24071 21738 20069 20300>,
			<12602 22908 23789 21460 19454 22218>,
			<12292 21605 23506 21176 18984 24100>,
			<12273 19428 23645 20877 19508 23428>,
			<12468 15767 24039 20595 20871 21332>,
			<12736 14118 24173 20582 21278 20028>,
			<13060 14947 24093 21185 20445 19314>,
			<13442 16177 23930 22032 19687 18940>,
			<13765 16798 23200 23069 20164 19159>,
			<14084 17167 21850 24163 21291 19829>,
			<14246 17731 21446 24356 21598 20590>,
			<14246 19279 21516 23940 21229 21686>,
			<14246 20933 21576 23372 20921 22404>,
			<14268 21565 21441 22691 20989 22221>,
			<14400 21939 21037 21957 21137 21824>,
			<14494 21922 20399 21566 21128 22266>,
			<14461 17945 19117 21334 20798 26231>,
			<14362 15085 18893 21387 20721 28749>,
			<13780 14749 19649 21944 21001 29783>,
			<13493 14172 19851 23438 25656 26976>,
			<13201 14176 19579 23220 20096 22770>,
			<13486 14132 16235 19503 18979 27612>,
			<13100 14277 16163 18608 24184 26757>,
			<13458 13920 16495 21225 25368 22437>,
			<13667 14040 16520 23155 21645 19191>,
			<12418 14294 15345 22678 23716 26453>,
			<10507 13088 14231 24110 29637 25942>,
			<9260 9877 13859 24593 27134 28349>,
			<8849 9026 10490 25015 27590 27484>,
			<8849 9026 10490 25015 27590 27484>,
			<8849 9026 10490 25015 27590 27484>;
	};

	qcom,pc-temp-y6-lut {
		qcom,lut-col-legend = <(-10) 0 10 25 40 50>;
		qcom,lut-row-legend = <10000 9800 9600 9400 9200 9000>,
			<8800 8600 8400 8200 8000 7800>,
			<7600 7400 7200 7000 6800 6600>,
			<6400 6200 6000 5800 5600 5400>,
			<5200 5000 4800 4600 4400 4200>,
			<4000 3800 3600 3400 3200 3000>,
			<2800 2600 2400 2200 2000 1800>,
			<1600 1400 1200 1000 900 800>,
			<700 600 500 400 300 200>,
			<100 0>;
		qcom,lut-data = <5644 5263 5128 4990 4962 4956>,
			<5652 5264 5133 4990 4962 4956>,
			<5655 5264 5135 4989 4962 4956>,
			<5655 5264 5135 4989 4962 4956>,
			<5653 5265 5134 4989 4962 4956>,
			<5650 5265 5132 4988 4962 4957>,
			<5643 5260 5127 4988 4962 4957>,
			<5634 5250 5121 4988 4962 4957>,
			<5628 5242 5116 4988 4963 4957>,
			<5624 5235 5112 4989 4963 4958>,
			<5619 5230 5109 4989 4964 4958>,
			<5614 5227 5107 4990 4965 4959>,
			<5609 5226 5107 4991 4966 4960>,
			<5611 5226 5107 4992 4967 4960>,
			<5630 5232 5108 4994 4969 4961>,
			<5642 5240 5109 4996 4970 4962>,
			<5614 5251 5115 4999 4972 4964>,
			<5566 5262 5122 5002 4974 4966>,
			<5546 5259 5127 5008 4977 4968>,
			<5538 5241 5132 5017 4982 4971>,
			<5530 5221 5133 5019 4984 4972>,
			<5521 5207 5114 5016 4982 4971>,
			<5510 5194 5089 5009 4979 4970>,
			<5501 5186 5076 4999 4973 4966>,
			<5492 5181 5068 4986 4964 4959>,
			<5488 5177 5064 4981 4961 4956>,
			<5494 5175 5062 4981 4961 4956>,
			<5509 5173 5062 4981 4961 4957>,
			<5525 5172 5062 4982 4961 4957>,
			<5542 5170 5063 4983 4963 4958>,
			<5561 5170 5063 4985 4965 4959>,
			<5583 5175 5063 4987 4966 4961>,
			<5608 5185 5062 4989 4968 4962>,
			<5635 5195 5063 4991 4971 4964>,
			<5666 5208 5065 4993 4973 4965>,
			<5700 5223 5067 4993 4973 4965>,
			<5736 5243 5074 4990 4967 4961>,
			<5775 5266 5081 4987 4962 4958>,
			<5816 5290 5088 4984 4962 4957>,
			<5862 5315 5094 4981 4961 4957>,
			<5910 5339 5102 4981 4961 4957>,
			<5960 5359 5112 4983 4961 4958>,
			<6017 5384 5127 4986 4962 4959>,
			<6085 5422 5148 4988 4962 4960>,
			<6180 5470 5169 4985 4959 4954>,
			<6272 5519 5175 4987 4962 4957>,
			<6361 5567 5197 4990 4964 4960>,
			<6485 5633 5234 4994 4968 4965>,
			<6682 5725 5286 5002 4978 4976>,
			<7020 5874 5349 5010 4984 4974>,
			<8207 6236 5429 5005 4966 4962>,
			<11377 7761 5618 5005 4970 4963>,
			<20889 13932 6212 5018 4974 4969>,
			<56092 42500 9771 5043 4989 4985>,
			<56092 42500 9771 5043 4989 4985>,
			<56092 42500 9771 5043 4989 4985>;
	};

};
